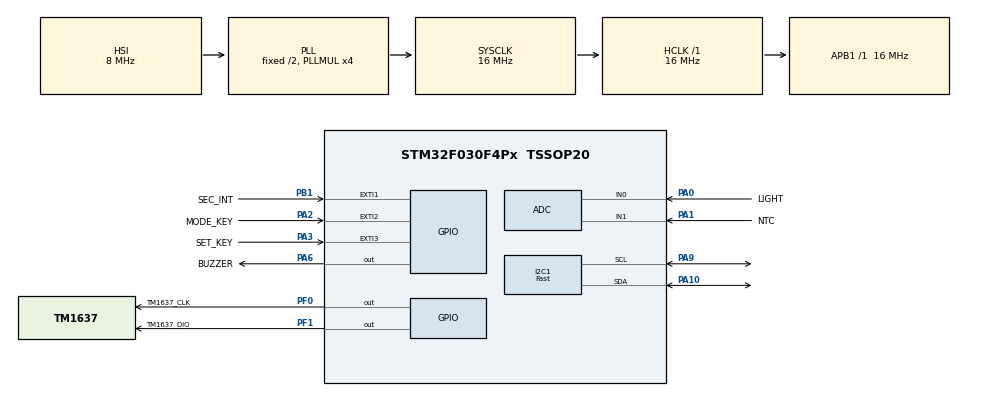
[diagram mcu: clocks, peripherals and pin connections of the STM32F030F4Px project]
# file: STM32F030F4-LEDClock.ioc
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ADC.ContinuousConvMode=ENABLE
ADC.DMAContinuousRequests=ENABLE
ADC.ExternalTrigConv=ADC_EXTERNALTRIGCONV_T3_TRGO
ADC.SamplingTime=ADC_SAMPLETIME_239CYCLES_5
Dma.ADC.0.Direction=DMA_PERIPH_TO_MEMORY
Dma.ADC.0.Instance=DMA1_Channel1
Dma.ADC.0.MemDataAlignment=DMA_MDATAALIGN_WORD
Dma.ADC.0.MemInc=DMA_MINC_ENABLE
Dma.ADC.0.Mode=DMA_CIRCULAR
Dma.ADC.0.PeriphDataAlignment=DMA_PDATAALIGN_WORD
Dma.ADC.0.PeriphInc=DMA_PINC_DISABLE
Dma.ADC.0.Priority=DMA_PRIORITY_LOW
Dma.Request0=ADC
I2C1.I2C_Speed_Mode=I2C_Fast
I2C1.Timing=0x0000020B
Mcu.Family=STM32F0
Mcu.Name=STM32F030F4Px
Mcu.Package=TSSOP20
NVIC.DMA1_Channel1_IRQn=true\:0\:0\:false\:false\:true\:false\:true
NVIC.EXTI0_1_IRQn=true\:0\:0\:true\:false\:true\:true\:true
NVIC.EXTI2_3_IRQn=true\:0\:0\:true\:false\:true\:true\:true
NVIC.TIM16_IRQn=true\:0\:0\:false\:false\:true\:true\:true
NVIC.TIM17_IRQn=true\:0\:0\:false\:false\:true\:true\:true
PA0.GPIO_Label=LIGHT
PA0.Mode=IN0
PA0.Signal=ADC_IN0
PA1.GPIO_Label=NTC
PA1.Mode=IN1
PA1.Signal=ADC_IN1
PA10.Mode=I2C
PA10.Signal=I2C1_SDA
PA13.Mode=Serial_Wire
PA13.Signal=SYS_SWDIO
PA14.Mode=Serial_Wire
PA14.Signal=SYS_SWCLK
PA2.GPIO_Label=MODE_KEY
PA2.GPIO_ModeDefaultEXTI=GPIO_MODE_IT_RISING_FALLING
PA2.GPIO_PuPd=GPIO_PULLUP
PA2.Signal=GPXTI2
PA3.GPIO_Label=SET_KEY
PA3.GPIO_ModeDefaultEXTI=GPIO_MODE_IT_RISING_FALLING
PA3.GPIO_PuPd=GPIO_PULLUP
PA3.Signal=GPXTI3
PA6.GPIO_Label=BUZZER
PA6.PinState=GPIO_PIN_SET
PA6.Signal=GPIO_Output
PA9.Mode=I2C
PA9.Signal=I2C1_SCL
PB1.GPIO_Label=SEC_INT
PB1.GPIO_ModeDefaultEXTI=GPIO_MODE_IT_FALLING
PB1.GPIO_PuPd=GPIO_PULLUP
PB1.Signal=GPXTI1
PF0-OSC_IN.GPIO_Label=TM1637_CLK
PF0-OSC_IN.GPIO_ModeDefaultOutputPP=GPIO_MODE_OUTPUT_OD
PF0-OSC_IN.GPIO_PuPd=GPIO_NOPULL
PF0-OSC_IN.GPIO_Speed=GPIO_SPEED_FREQ_MEDIUM
PF0-OSC_IN.PinState=GPIO_PIN_SET
PF0-OSC_IN.Signal=GPIO_Output
PF1-OSC_OUT.GPIO_Label=TM1637_DIO
PF1-OSC_OUT.GPIO_ModeDefaultOutputPP=GPIO_MODE_OUTPUT_OD
PF1-OSC_OUT.GPIO_PuPd=GPIO_NOPULL
PF1-OSC_OUT.GPIO_Speed=GPIO_SPEED_FREQ_MEDIUM
PF1-OSC_OUT.PinState=GPIO_PIN_SET
PF1-OSC_OUT.Signal=GPIO_Output
ProjectManager.HeapSize=0x200
ProjectManager.StackSize=0x400
ProjectManager.TargetToolchain=Makefile
RCC.AHBFreq_Value=16000000
RCC.APB1Freq_Value=16000000
RCC.APB1TimFreq_Value=16000000
RCC.HCLKFreq_Value=16000000
RCC.PLLMUL=RCC_PLL_MUL4
RCC.SYSCLKFreq_VALUE=16000000
RCC.SYSCLKSource=RCC_SYSCLKSOURCE_PLLCLK
TIM16.AutoReloadPreload=TIM_AUTORELOAD_PRELOAD_ENABLE
TIM16.Period=9999
TIM16.Prescaler=1599
TIM17.AutoReloadPreload=TIM_AUTORELOAD_PRELOAD_ENABLE
TIM17.Period=999
TIM17.Prescaler=15
TIM3.Period=9999
TIM3.Prescaler=15
TIM3.TIM_MasterOutputTrigger=TIM_TRGO_UPDATE
VP_TIM16_VS_ClockSourceINT.Mode=Enable_Timer
VP_TIM17_VS_ClockSourceINT.Mode=Enable_Timer
VP_TIM3_VS_ClockSourceINT.Mode=Internal
board=custom

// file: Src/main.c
/* USER CODE BEGIN Header */
/**
 ******************************************************************************
 * @file           : main.c
 * @brief          : Main program body
 ******************************************************************************
 * @attention
 *
 * <h2><center>&copy; Copyright (c) 2019 STMicroelectronics.
 * All rights reserved.</center></h2>
 *
 * This software component is licensed by ST under BSD 3-Clause license,
 * the "License"; You may not use this file except in compliance with the
 * License. You may obtain a copy of the License at:
 *                        opensource.org/licenses/BSD-3-Clause
 *
 ******************************************************************************
 */
/* USER CODE END Header */

#include "main.h"
#include "adc.h"
#include "dma.h"
#include "gpio.h"
#include "i2c.h"
#include "tim.h"

/* USER CODE BEGIN Includes */
#include "app.h"
/* USER CODE END Includes */

void SystemClock_Config(void);

int main(void) {

  /* MCU Configuration--------------------------------------------------------*/

  /* Reset of all peripherals, Initializes the Flash interface and the Systick.
   */
  HAL_Init();

  /* Configure the system clock */
  SystemClock_Config();

  /* Initialize all configured peripherals */
  MX_GPIO_Init();
  MX_DMA_Init();
  MX_I2C1_Init();
  MX_ADC_Init();
  MX_TIM17_Init();
  MX_TIM3_Init();
  MX_TIM16_Init();
  /* USER CODE BEGIN 2 */

  /* 应用初始化 */
  App_Init();

  /* USER CODE END 2 */

  /* Infinite loop */
  while (1) {

    /* USER CODE BEGIN 3 */
    /* 应用主循环处理 */
    App_MainLoop();
  }
  /* USER CODE END 3 */
}

void SystemClock_Config(void) {
  RCC_OscInitTypeDef RCC_OscInitStruct = {0};
  RCC_ClkInitTypeDef RCC_ClkInitStruct = {0};
  RCC_PeriphCLKInitTypeDef PeriphClkInit = {0};

  /** Initializes the CPU, AHB and APB busses clocks
   */
  RCC_OscInitStruct.OscillatorType =
      RCC_OSCILLATORTYPE_HSI | RCC_OSCILLATORTYPE_HSI14;
  RCC_OscInitStruct.HSIState = RCC_HSI_ON;
  RCC_OscInitStruct.HSI14State = RCC_HSI14_ON;
  RCC_OscInitStruct.HSICalibrationValue = RCC_HSICALIBRATION_DEFAULT;
  RCC_OscInitStruct.HSI14CalibrationValue = 16;
  RCC_OscInitStruct.PLL.PLLState = RCC_PLL_ON;
  RCC_OscInitStruct.PLL.PLLSource = RCC_PLLSOURCE_HSI;
  RCC_OscInitStruct.PLL.PLLMUL = RCC_PLL_MUL4;
  RCC_OscInitStruct.PLL.PREDIV = RCC_PREDIV_DIV1;
  if (HAL_RCC_OscConfig(&RCC_OscInitStruct) != HAL_OK) {
    Error_Handler();
  }
  /** Initializes the CPU, AHB and APB busses clocks
   */
  RCC_ClkInitStruct.ClockType =
      RCC_CLOCKTYPE_HCLK | RCC_CLOCKTYPE_SYSCLK | RCC_CLOCKTYPE_PCLK1;
  RCC_ClkInitStruct.SYSCLKSource = RCC_SYSCLKSOURCE_PLLCLK;
  RCC_ClkInitStruct.AHBCLKDivider = RCC_SYSCLK_DIV1;
  RCC_ClkInitStruct.APB1CLKDivider = RCC_HCLK_DIV1;

  if (HAL_RCC_ClockConfig(&RCC_ClkInitStruct, FLASH_LATENCY_0) != HAL_OK) {
    Error_Handler();
  }
  PeriphClkInit.PeriphClockSelection = RCC_PERIPHCLK_I2C1;
  PeriphClkInit.I2c1ClockSelection = RCC_I2C1CLKSOURCE_HSI;
  if (HAL_RCCEx_PeriphCLKConfig(&PeriphClkInit) != HAL_OK) {
    Error_Handler();
  }
}

/* USER CODE BEGIN 4 */
#include "app.h"

/**
 * @brief  GPIO 外部中断回调
 */
void HAL_GPIO_EXTI_Callback(uint16_t GPIO_Pin) {
  App_GPIO_EXTI_Callback(GPIO_Pin);
}

/**
 * @brief  定时器周期回调
 */
void HAL_TIM_PeriodElapsedCallback(TIM_HandleTypeDef *htim) {
  App_TIM_PeriodElapsedCallback(htim);
}

/* USER CODE END 4 */

void Error_Handler(void) {
}

#ifdef USE_FULL_ASSERT
/**
 * @brief  Reports the name of the source file and the source line number
 *         where the assert_param error has occurred.
 * @param  file: pointer to the source file name
 * @param  line: assert_param error line source number
 * @retval None
 */
void assert_failed(char *file, uint32_t line) {
  /* USER CODE BEGIN 6 */
  /* User can add his own implementation to report the file name and line
     number, tex: printf("Wrong parameters value: file %s on line %d\r\n", file,
     line) */
  /* USER CODE END 6 */
}
#endif /* USE_FULL_ASSERT */

/************************ (C) COPYRIGHT STMicroelectronics *****END OF FILE****/
